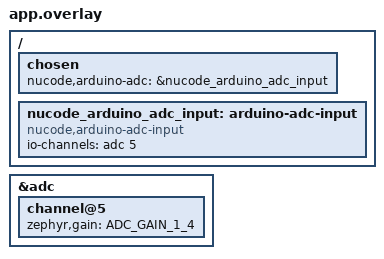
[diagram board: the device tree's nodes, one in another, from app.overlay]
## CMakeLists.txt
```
cmake_minimum_required(VERSION 3.20.0)

find_package(Zephyr REQUIRED HINTS $ENV{ZEPHYR_BASE})
project(nucode_arduino_analog_read_a0)

target_sources(app PRIVATE src/analog_read_a0.cpp)
```

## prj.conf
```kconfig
CONFIG_CPP=y
CONFIG_STD_CPP17=y
CONFIG_CPP_EXCEPTIONS=n
CONFIG_CPP_RTTI=n

CONFIG_NUCODE_ARDUINO_CORE=y
CONFIG_NUCODE_ARDUINO_RUNTIME=y
CONFIG_NUCODE_ARDUINO_API=y
CONFIG_NUCODE_ARDUINO_GPIO=n
CONFIG_NUCODE_ARDUINO_INTERRUPTS=n
CONFIG_NUCODE_ARDUINO_TIME=y
CONFIG_NUCODE_ARDUINO_SERIAL=y
CONFIG_NUCODE_ARDUINO_WIRE=n
CONFIG_NUCODE_ARDUINO_SPI=n
CONFIG_NUCODE_ARDUINO_ADC=y
CONFIG_NUCODE_ARDUINO_PWM=n

CONFIG_MAIN_STACK_SIZE=4096
CONFIG_HEAP_MEM_POOL_SIZE=0
CONFIG_COMMON_LIBC_MALLOC_ARENA_SIZE=8192
```

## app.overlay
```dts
/** @brief A0를 board SAADC channel 5/P1.12 io-channel로 선택합니다. */
/ {
	chosen {
		nucode,arduino-adc = &nucode_arduino_adc_input;
	};

	nucode_arduino_adc_input: arduino-adc-input {
		compatible = "nucode,arduino-adc-input";
		io-channels = <&adc 5>;
	};
};

/** @brief nRF54L15이 지원하는 가장 낮은 1/4 gain으로 A0 입력 범위를 설정합니다. */
&adc {
	channel@5 {
		zephyr,gain = "ADC_GAIN_1_4";
	};
};
```

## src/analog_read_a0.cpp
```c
/**
 * @file analog_read_a0.cpp
 * @brief NU54DK A0/P1.12의 고정 12-bit raw ADC 값을 출력합니다.
 *
 * SPDX-License-Identifier: MIT
 */

#include <Arduino.h>

/** @brief Serial과 DTS 고정 reference 계약을 시작합니다. */
void setup(void)
{
    Serial.begin(115200U);
    analogReference(AR_DEFAULT);
}

/** @brief A0 raw 값 0..4095 또는 오류 -1을 출력합니다. */
void loop(void)
{
    const int raw = analogRead(A0);
    Serial.print("NUCODE_M7_A0_RAW:");
    Serial.println(raw);
    delay(250U);
}
```
